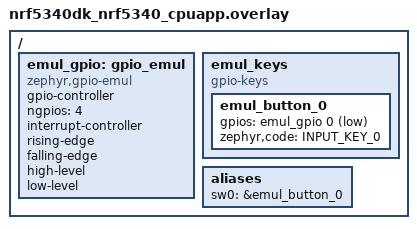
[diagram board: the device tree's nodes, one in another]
/* Test image overlay for the nRF5340 DK: only the button is emulated, the LED
 * stays on the real LED1. Replaces app.overlay for this board, so the GPIO
 * emulator is declared again here. */
#include <zephyr/dt-bindings/gpio/gpio.h>
#include <zephyr/dt-bindings/input/input-event-codes.h>

/ {
    emul_gpio: gpio_emul {
        compatible = "zephyr,gpio-emul";
        status = "okay";
        gpio-controller;
        #gpio-cells = <2>;
        ngpios = <4>;
        interrupt-controller;
        #interrupt-cells = <2>;
        rising-edge;
        falling-edge;
        high-level;
        low-level;
    };

    emul_keys {
        compatible = "gpio-keys";
        emul_button_0: emul_button_0 {
            gpios = <&emul_gpio 0 GPIO_ACTIVE_LOW>;
            zephyr,code = <INPUT_KEY_0>;
        };
    };

    /* sw0 moves to the emulator so pytest can press it; the physical button
     * does nothing in this image. */
    aliases {
        sw0 = &emul_button_0;
    };
};
